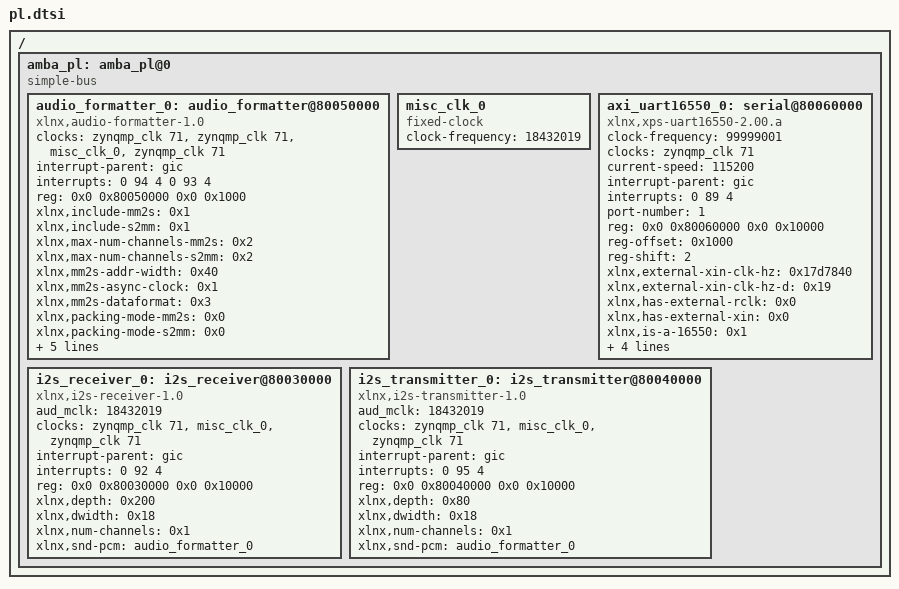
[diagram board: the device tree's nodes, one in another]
/*
 * CAUTION: This file is automatically generated by Xilinx.
 * Version:  
 * Today is: Thu Jun 18 20:39:03 2020
 */


/ {
	amba_pl: amba_pl@0 {
		#address-cells = <2>;
		#size-cells = <2>;
		compatible = "simple-bus";
		ranges ;
		audio_formatter_0: audio_formatter@80050000 {
			clock-names = "s_axi_lite_aclk", "m_axis_mm2s_aclk", "aud_mclk", "s_axis_s2mm_aclk";
			clocks = <&zynqmp_clk 71>, <&zynqmp_clk 71>, <&misc_clk_0>, <&zynqmp_clk 71>;
			compatible = "xlnx,audio-formatter-1.0", "xlnx,audio-formatter-1.0";
			interrupt-names = "irq_mm2s", "irq_s2mm";
			interrupt-parent = <&gic>;
			interrupts = <0 94 4 0 93 4>;
			reg = <0x0 0x80050000 0x0 0x1000>;
			xlnx,include-mm2s = <0x1>;
			xlnx,include-s2mm = <0x1>;
			xlnx,max-num-channels-mm2s = <0x2>;
			xlnx,max-num-channels-s2mm = <0x2>;
			xlnx,mm2s-addr-width = <0x40>;
			xlnx,mm2s-async-clock = <0x1>;
			xlnx,mm2s-dataformat = <0x3>;
			xlnx,packing-mode-mm2s = <0x0>;
			xlnx,packing-mode-s2mm = <0x0>;
			xlnx,rx = <&i2s_receiver_0>;
			xlnx,s2mm-addr-width = <0x40>;
			xlnx,s2mm-async-clock = <0x1>;
			xlnx,s2mm-dataformat = <0x1>;
			xlnx,tx = <&i2s_transmitter_0>;
		};
		misc_clk_0: misc_clk_0 {
			#clock-cells = <0>;
			clock-frequency = <18432019>;
			compatible = "fixed-clock";
		};
		axi_uart16550_0: serial@80060000 {
			clock-frequency = <99999001>;
			clock-names = "s_axi_aclk";
			clocks = <&zynqmp_clk 71>;
			compatible = "xlnx,xps-uart16550-2.00.a", "ns16550a";
			current-speed = <115200>;
			device_type = "serial";
			interrupt-names = "ip2intc_irpt";
			interrupt-parent = <&gic>;
			interrupts = <0 89 4>;
			port-number = <1>;
			reg = <0x0 0x80060000 0x0 0x10000>;
			reg-offset = <0x1000>;
			reg-shift = <2>;
			xlnx,external-xin-clk-hz = <0x17d7840>;
			xlnx,external-xin-clk-hz-d = <0x19>;
			xlnx,has-external-rclk = <0x0>;
			xlnx,has-external-xin = <0x0>;
			xlnx,is-a-16550 = <0x1>;
			xlnx,s-axi-aclk-freq-hz-d = "99.999001";
			xlnx,sim-device = "VERSAL_AI_CORE_ES1";
			xlnx,use-modem-ports = <0x1>;
			xlnx,use-user-ports = <0x1>;
		};
		i2s_receiver_0: i2s_receiver@80030000 {
			aud_mclk = <18432019>;
			clock-names = "s_axi_ctrl_aclk", "aud_mclk", "m_axis_aud_aclk";
			clocks = <&zynqmp_clk 71>, <&misc_clk_0>, <&zynqmp_clk 71>;
			compatible = "xlnx,i2s-receiver-1.0", "xlnx,i2s-receiver-1.0";
			interrupt-names = "irq";
			interrupt-parent = <&gic>;
			interrupts = <0 92 4>;
			reg = <0x0 0x80030000 0x0 0x10000>;
			xlnx,depth = <0x200>;
			xlnx,dwidth = <0x18>;
			xlnx,num-channels = <0x1>;
			xlnx,snd-pcm = <&audio_formatter_0>;
		};
		i2s_transmitter_0: i2s_transmitter@80040000 {
			aud_mclk = <18432019>;
			clock-names = "s_axi_ctrl_aclk", "aud_mclk", "s_axis_aud_aclk";
			clocks = <&zynqmp_clk 71>, <&misc_clk_0>, <&zynqmp_clk 71>;
			compatible = "xlnx,i2s-transmitter-1.0", "xlnx,i2s-transmitter-1.0";
			interrupt-names = "irq";
			interrupt-parent = <&gic>;
			interrupts = <0 95 4>;
			reg = <0x0 0x80040000 0x0 0x10000>;
			xlnx,depth = <0x80>;
			xlnx,dwidth = <0x18>;
			xlnx,num-channels = <0x1>;
			xlnx,snd-pcm = <&audio_formatter_0>;
		};
	
	};
};
